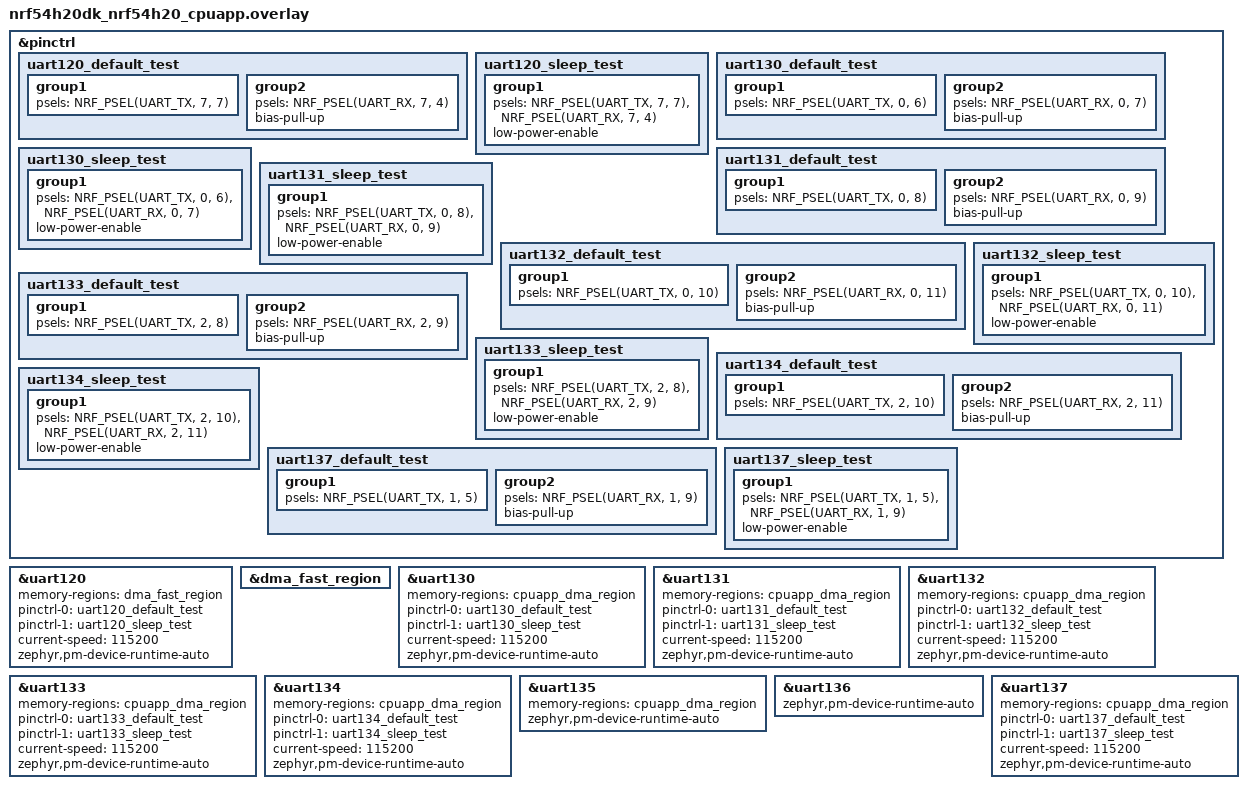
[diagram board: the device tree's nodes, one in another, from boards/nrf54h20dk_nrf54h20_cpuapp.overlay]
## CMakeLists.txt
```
# SPDX-License-Identifier: LicenseRef-Nordic-5-Clause

cmake_minimum_required(VERSION 3.20.0)

find_package(Zephyr REQUIRED HINTS $ENV{ZEPHYR_BASE})
project(uart_instances)

FILE(GLOB app_sources src/*.c)
target_sources(app PRIVATE ${app_sources})
```

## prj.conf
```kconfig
CONFIG_ZTEST=y
CONFIG_TEST_USERSPACE=y
CONFIG_SERIAL=y
CONFIG_UART_USE_RUNTIME_CONFIGURE=y
CONFIG_UART_ASYNC_API=y
```

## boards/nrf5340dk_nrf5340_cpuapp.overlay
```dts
/*
 * Copyright (c) 2026 Nordic Semiconductor ASA
 *
 * SPDX-License-Identifier: LicenseRef-Nordic-5-Clause
 */

&pinctrl {
	uart1_default_test: uart1_default_test {
		group1 {
			psels = <NRF_PSEL(UART_TX, 0, 4)>,
				<NRF_PSEL(UART_RX, 0, 6)>;
			bias-pull-up;
		};
	};

	uart1_sleep_test: uart1_sleep_test {
		group1 {
			psels = <NRF_PSEL(UART_TX, 0, 4)>,
				<NRF_PSEL(UART_RX, 0, 6)>;
			low-power-enable;
		};
	};

	uart2_default_test: uart2_default_test {
		group1 {
			psels = <NRF_PSEL(UART_TX, 1, 4)>,
				<NRF_PSEL(UART_RX, 1, 6)>;
			bias-pull-up;
		};
	};

	uart2_sleep_test: uart2_sleep_test {
		group1 {
			psels = <NRF_PSEL(UART_TX, 1, 4)>,
				<NRF_PSEL(UART_RX, 1, 6)>;
			low-power-enable;
		};
	};

	uart3_default_test: uart3_default_test {
		group1 {
			psels = <NRF_PSEL(UART_TX, 1, 2)>,
				<NRF_PSEL(UART_RX, 1, 3)>;
			bias-pull-up;
		};
	};

	uart3_sleep_test: uart3_sleep_test {
		group1 {
			psels = <NRF_PSEL(UART_TX, 1, 2)>,
				<NRF_PSEL(UART_RX, 1, 3)>;
			low-power-enable;
		};
	};
};

&uart1 {
	status = "okay";
	current-speed = <115200>;
	pinctrl-0 = <&uart1_default_test>;
	pinctrl-1 = <&uart1_sleep_test>;
	pinctrl-names = "default", "sleep";
};

&uart2 {
	status = "okay";
	current-speed = <115200>;
	pinctrl-0 = <&uart2_default_test>;
	pinctrl-1 = <&uart2_sleep_test>;
	pinctrl-names = "default", "sleep";
};

&uart3 {
	status = "okay";
	current-speed = <115200>;
	pinctrl-0 = <&uart3_default_test>;
	pinctrl-1 = <&uart3_sleep_test>;
	pinctrl-names = "default", "sleep";
};
```

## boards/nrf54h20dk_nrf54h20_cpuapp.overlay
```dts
/*
 * Copyright (c) 2025 Nordic Semiconductor ASA
 *
 * SPDX-License-Identifier: LicenseRef-Nordic-5-Clause
 */

&pinctrl {
	uart120_default_test: uart120_default_test {
		group1 {
			psels = <NRF_PSEL(UART_TX, 7, 7)>;
		};

		group2 {
			psels = <NRF_PSEL(UART_RX, 7, 4)>;
			bias-pull-up;
		};
	};

	uart120_sleep_test: uart120_sleep_test {
		group1 {
			psels = <NRF_PSEL(UART_TX, 7, 7)>,
				<NRF_PSEL(UART_RX, 7, 4)>;
			low-power-enable;
		};
	};

	uart130_default_test: uart130_default_test {
		group1 {
			psels = <NRF_PSEL(UART_TX, 0, 6)>;
		};

		group2 {
			psels = <NRF_PSEL(UART_RX, 0, 7)>;
			bias-pull-up;
		};
	};

	uart130_sleep_test: uart130_sleep_test {
		group1 {
			psels = <NRF_PSEL(UART_TX, 0, 6)>,
				<NRF_PSEL(UART_RX, 0, 7)>;
			low-power-enable;
		};
	};

	uart131_default_test: uart131_default_test {
		group1 {
			psels = <NRF_PSEL(UART_TX, 0, 8)>;
		};

		group2 {
			psels = <NRF_PSEL(UART_RX, 0, 9)>;
			bias-pull-up;
		};
	};

	uart131_sleep_test: uart131_sleep_test {
		group1 {
			psels = <NRF_PSEL(UART_TX, 0, 8)>,
				<NRF_PSEL(UART_RX, 0, 9)>;
			low-power-enable;
		};
	};

	uart132_default_test: uart132_default_test {
		group1 {
			psels = <NRF_PSEL(UART_TX, 0, 10)>;
		};

		group2 {
			psels = <NRF_PSEL(UART_RX, 0, 11)>;
			bias-pull-up;
		};
	};

	uart132_sleep_test: uart132_sleep_test {
		group1 {
			psels = <NRF_PSEL(UART_TX, 0, 10)>,
				<NRF_PSEL(UART_RX, 0, 11)>;
			low-power-enable;
		};
	};

	uart133_default_test: uart133_default_test {
		group1 {
			psels = <NRF_PSEL(UART_TX, 2, 8)>;
		};

		group2 {
			psels = <NRF_PSEL(UART_RX, 2, 9)>;
			bias-pull-up;
		};
	};

	uart133_sleep_test: uart133_sleep_test {
		group1 {
			psels = <NRF_PSEL(UART_TX, 2, 8)>,
				<NRF_PSEL(UART_RX, 2, 9)>;
			low-power-enable;
		};
	};

	uart134_default_test: uart134_default_test {
		group1 {
			psels = <NRF_PSEL(UART_TX, 2, 10)>;
		};

		group2 {
			psels = <NRF_PSEL(UART_RX, 2, 11)>;
			bias-pull-up;
		};
	};

	uart134_sleep_test: uart134_sleep_test {
		group1 {
			psels = <NRF_PSEL(UART_TX, 2, 10)>,
				<NRF_PSEL(UART_RX, 2, 11)>;
			low-power-enable;
		};
	};

	/* use default pinctrl for uart135 */

	/* use default pinctrl for uart136 */

	uart137_default_test: uart137_default_test {
		group1 {
			psels = <NRF_PSEL(UART_TX, 1, 5)>;
		};

		group2 {
			psels = <NRF_PSEL(UART_RX, 1, 9)>;
			bias-pull-up;
		};
	};

	uart137_sleep_test: uart137_sleep_test {
		group1 {
			psels = <NRF_PSEL(UART_TX, 1, 5)>,
				<NRF_PSEL(UART_RX, 1, 9)>;
			low-power-enable;
		};
	};
};

&uart120 {
	status = "okay";
	memory-regions = <&dma_fast_region>;
	pinctrl-0 = <&uart120_default_test>;
	pinctrl-1 = <&uart120_sleep_test>;
	pinctrl-names = "default", "sleep";
	current-speed = <115200>;
	zephyr,pm-device-runtime-auto;
};

&dma_fast_region {
	status = "okay";
};

&uart130 {
	status = "okay";
	memory-regions = <&cpuapp_dma_region>;
	pinctrl-0 = <&uart130_default_test>;
	pinctrl-1 = <&uart130_sleep_test>;
	pinctrl-names = "default", "sleep";
	current-speed = <115200>;
	zephyr,pm-device-runtime-auto;
};

&uart131 {
	status = "okay";
	memory-regions = <&cpuapp_dma_region>;
	pinctrl-0 = <&uart131_default_test>;
	pinctrl-1 = <&uart131_sleep_test>;
	pinctrl-names = "default", "sleep";
	current-speed = <115200>;
	zephyr,pm-device-runtime-auto;
};

&uart132 {
	status = "okay";
	memory-regions = <&cpuapp_dma_region>;
	pinctrl-0 = <&uart132_default_test>;
	pinctrl-1 = <&uart132_sleep_test>;
	pinctrl-names = "default", "sleep";
	current-speed = <115200>;
	zephyr,pm-device-runtime-auto;
};

&uart133 {
	status = "okay";
	memory-regions = <&cpuapp_dma_region>;
	pinctrl-0 = <&uart133_default_test>;
	pinctrl-1 = <&uart133_sleep_test>;
	pinctrl-names = "default", "sleep";
	current-speed = <115200>;
	zephyr,pm-device-runtime-auto;
};

&uart134 {
	status = "okay";
	memory-regions = <&cpuapp_dma_region>;
	pinctrl-0 = <&uart134_default_test>;
	pinctrl-1 = <&uart134_sleep_test>;
	pinctrl-names = "default", "sleep";
	current-speed = <115200>;
	zephyr,pm-device-runtime-auto;
};

&uart135 {
	status = "okay";
	memory-regions = <&cpuapp_dma_region>;
	zephyr,pm-device-runtime-auto;
};

&uart136 {
	status = "okay";
	zephyr,pm-device-runtime-auto;
};

&uart137 {
	status = "okay";
	memory-regions = <&cpuapp_dma_region>;
	pinctrl-0 = <&uart137_default_test>;
	pinctrl-1 = <&uart137_sleep_test>;
	pinctrl-names = "default", "sleep";
	current-speed = <115200>;
	zephyr,pm-device-runtime-auto;
};
```

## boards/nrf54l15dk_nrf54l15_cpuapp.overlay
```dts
/*
 * Copyright (c) 2025 Nordic Semiconductor ASA
 *
 * SPDX-License-Identifier: LicenseRef-Nordic-5-Clause
 */

&pinctrl {
	uart00_default_test: uart00_default_test {
		group1 {
			psels = <NRF_PSEL(UART_TX, 2, 8)>,
				<NRF_PSEL(UART_RX, 2, 7)>;
			bias-pull-up;
		};
	};

	uart00_sleep_test: uart00_sleep_test {
		group1 {
			psels = <NRF_PSEL(UART_TX, 2, 8)>,
				<NRF_PSEL(UART_RX, 2, 7)>;
			low-power-enable;
		};
	};

	/* Use default configuration for uart20 */

	uart21_default_test: uart21_default_test {
		group1 {
			psels = <NRF_PSEL(UART_TX, 1, 10)>,
				<NRF_PSEL(UART_RX, 1, 8)>;
			bias-pull-up;
		};
	};

	uart21_sleep_test: uart21_sleep_test {
		group1 {
			psels = <NRF_PSEL(UART_TX, 1, 10)>,
				<NRF_PSEL(UART_RX, 1, 8)>;
			low-power-enable;
		};
	};

	uart22_default_test: uart22_default_test {
		group1 {
			psels = <NRF_PSEL(UART_TX, 1, 9)>,
				<NRF_PSEL(UART_RX, 1, 11)>;
			bias-pull-up;
		};
	};

	uart22_sleep_test: uart22_sleep_test {
		group1 {
			psels = <NRF_PSEL(UART_TX, 1, 9)>,
				<NRF_PSEL(UART_RX, 1, 11)>;
			low-power-enable;
		};
	};

	/* Use default configuration for uart30 */
};

&uart00 {
	status = "okay";
	current-speed = <115200>;
	pinctrl-0 = <&uart00_default_test>;
	pinctrl-1 = <&uart00_sleep_test>;
	pinctrl-names = "default", "sleep";
};

&uart20 {
	status = "okay";
};

&uart21 {
	status = "okay";
	current-speed = <115200>;
	pinctrl-0 = <&uart21_default_test>;
	pinctrl-1 = <&uart21_sleep_test>;
	pinctrl-names = "default", "sleep";
};

&uart22 {
	status = "okay";
	current-speed = <115200>;
	pinctrl-0 = <&uart22_default_test>;
	pinctrl-1 = <&uart22_sleep_test>;
	pinctrl-names = "default", "sleep";
};

&uart30 {
	status = "okay";
};
```

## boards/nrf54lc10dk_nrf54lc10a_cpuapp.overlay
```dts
/*
 * Copyright (c) 2026 Nordic Semiconductor ASA
 *
 * SPDX-License-Identifier: LicenseRef-Nordic-5-Clause
 */

&pinctrl {
	uart20_default_test: uart20_default_test {
		group1 {
			psels = <NRF_PSEL(UART_TX, 1, 2)>,
				<NRF_PSEL(UART_RX, 1, 3)>;
			bias-pull-up;
		};
	};

	uart20_sleep_test: uart20_sleep_test {
		group1 {
			psels = <NRF_PSEL(UART_TX, 1, 2)>,
				<NRF_PSEL(UART_RX, 1, 3)>;
			low-power-enable;
		};
	};

	uart21_default_test: uart21_default_test {
		group1 {
			psels = <NRF_PSEL(UART_TX, 1, 4)>,
				<NRF_PSEL(UART_RX, 1, 5)>;
			bias-pull-up;
		};
	};

	uart21_sleep_test: uart21_sleep_test {
		group1 {
			psels = <NRF_PSEL(UART_TX, 1, 4)>,
				<NRF_PSEL(UART_RX, 1, 5)>;
			low-power-enable;
		};
	};
};

&uart20 {
	status = "okay";
	current-speed = <115200>;
	pinctrl-0 = <&uart20_default_test>;
	pinctrl-1 = <&uart20_sleep_test>;
	pinctrl-names = "default", "sleep";
};

&uart21 {
	status = "okay";
	current-speed = <115200>;
	pinctrl-0 = <&uart21_default_test>;
	pinctrl-1 = <&uart21_sleep_test>;
	pinctrl-names = "default", "sleep";
};

&uart30 {
	status = "okay";
};

&gpio1 {
	status = "okay";
};
```

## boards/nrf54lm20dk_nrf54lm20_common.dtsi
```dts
/*
 * Copyright (c) 2026 Nordic Semiconductor ASA
 *
 * SPDX-License-Identifier: LicenseRef-Nordic-5-Clause
 */

&pinctrl {
	uart00_default_test: uart00_default_test {
		group1 {
			psels = <NRF_PSEL(UART_TX, 2, 2)>,
				<NRF_PSEL(UART_RX, 2, 1)>;
			bias-pull-up;
		};
	};

	uart00_sleep_test: uart00_sleep_test {
		group1 {
			psels = <NRF_PSEL(UART_TX, 2, 2)>,
				<NRF_PSEL(UART_RX, 2, 1)>;
			low-power-enable;
		};
	};

	/* Use default configuration for uart20 */

	uart21_default_test: uart21_default_test {
		group1 {
			psels = <NRF_PSEL(UART_TX, 3, 0)>,
				<NRF_PSEL(UART_RX, 3, 1)>;
			bias-pull-up;
		};
	};

	uart21_sleep_test: uart21_sleep_test {
		group1 {
			psels = <NRF_PSEL(UART_TX, 3, 0)>,
				<NRF_PSEL(UART_RX, 3, 1)>;
			low-power-enable;
		};
	};

	uart22_default_test: uart22_default_test {
		group1 {
			psels = <NRF_PSEL(UART_TX, 3, 2)>,
				<NRF_PSEL(UART_RX, 3, 3)>;
			bias-pull-up;
		};
	};

	uart22_sleep_test: uart22_sleep_test {
		group1 {
			psels = <NRF_PSEL(UART_TX, 3, 2)>,
				<NRF_PSEL(UART_RX, 3, 3)>;
			low-power-enable;
		};
	};

	uart23_default_test: uart23_default_test {
		group1 {
			psels = <NRF_PSEL(UART_TX, 3, 4)>,
				<NRF_PSEL(UART_RX, 3, 5)>;
			bias-pull-up;
		};
	};

	uart23_sleep_test: uart23_sleep_test {
		group1 {
			psels = <NRF_PSEL(UART_TX, 3, 4)>,
				<NRF_PSEL(UART_RX, 3, 5)>;
			low-power-enable;
		};
	};

	uart24_default_test: uart24_default_test {
		group1 {
			psels = <NRF_PSEL(UART_TX, 3, 6)>,
				<NRF_PSEL(UART_RX, 3, 7)>;
			bias-pull-up;
		};
	};

	uart24_sleep_test: uart24_sleep_test {
		group1 {
			psels = <NRF_PSEL(UART_TX, 3, 6)>,
				<NRF_PSEL(UART_RX, 3, 7)>;
			low-power-enable;
		};
	};

	/* Use default configuration for uart30 */
};

&uart00 {
	status = "okay";
	current-speed = <115200>;
	pinctrl-0 = <&uart00_default_test>;
	pinctrl-1 = <&uart00_sleep_test>;
	pinctrl-names = "default", "sleep";
};

&uart20 {
	status = "okay";
};

&uart21 {
	status = "okay";
	current-speed = <115200>;
	pinctrl-0 = <&uart21_default_test>;
	pinctrl-1 = <&uart21_sleep_test>;
	pinctrl-names = "default", "sleep";
};

&uart22 {
	status = "okay";
	current-speed = <115200>;
	pinctrl-0 = <&uart22_default_test>;
	pinctrl-1 = <&uart22_sleep_test>;
	pinctrl-names = "default", "sleep";
};

&uart23 {
	status = "okay";
	current-speed = <115200>;
	pinctrl-0 = <&uart23_default_test>;
	pinctrl-1 = <&uart23_sleep_test>;
	pinctrl-names = "default", "sleep";
};

&uart24 {
	status = "okay";
	current-speed = <115200>;
	pinctrl-0 = <&uart24_default_test>;
	pinctrl-1 = <&uart24_sleep_test>;
	pinctrl-names = "default", "sleep";
};

&uart30 {
	status = "okay";
};
```

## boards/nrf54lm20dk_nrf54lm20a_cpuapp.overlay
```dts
/*
 * Copyright (c) 2025 Nordic Semiconductor ASA
 *
 * SPDX-License-Identifier: LicenseRef-Nordic-5-Clause
 */

&pinctrl {
	uart00_default_test: uart00_default_test {
		group1 {
			psels = <NRF_PSEL(UART_TX, 2, 2)>,
				<NRF_PSEL(UART_RX, 2, 1)>;
			bias-pull-up;
		};
	};

	uart00_sleep_test: uart00_sleep_test {
		group1 {
			psels = <NRF_PSEL(UART_TX, 2, 2)>,
				<NRF_PSEL(UART_RX, 2, 1)>;
			low-power-enable;
		};
	};

	/* Use default configuration for uart20 */

	uart21_default_test: uart21_default_test {
		group1 {
			psels = <NRF_PSEL(UART_TX, 3, 0)>,
				<NRF_PSEL(UART_RX, 3, 1)>;
			bias-pull-up;
		};
	};

	uart21_sleep_test: uart21_sleep_test {
		group1 {
			psels = <NRF_PSEL(UART_TX, 3, 0)>,
				<NRF_PSEL(UART_RX, 3, 1)>;
			low-power-enable;
		};
	};

	uart22_default_test: uart22_default_test {
		group1 {
			psels = <NRF_PSEL(UART_TX, 3, 2)>,
				<NRF_PSEL(UART_RX, 3, 3)>;
			bias-pull-up;
		};
	};

	uart22_sleep_test: uart22_sleep_test {
		group1 {
			psels = <NRF_PSEL(UART_TX, 3, 2)>,
				<NRF_PSEL(UART_RX, 3, 3)>;
			low-power-enable;
		};
	};

	uart23_default_test: uart23_default_test {
		group1 {
			psels = <NRF_PSEL(UART_TX, 3, 4)>,
				<NRF_PSEL(UART_RX, 3, 5)>;
			bias-pull-up;
		};
	};

	uart23_sleep_test: uart23_sleep_test {
		group1 {
			psels = <NRF_PSEL(UART_TX, 3, 4)>,
				<NRF_PSEL(UART_RX, 3, 5)>;
			low-power-enable;
		};
	};

	uart24_default_test: uart24_default_test {
		group1 {
			psels = <NRF_PSEL(UART_TX, 3, 6)>,
				<NRF_PSEL(UART_RX, 3, 7)>;
			bias-pull-up;
		};
	};

	uart24_sleep_test: uart24_sleep_test {
		group1 {
			psels = <NRF_PSEL(UART_TX, 3, 6)>,
				<NRF_PSEL(UART_RX, 3, 7)>;
			low-power-enable;
		};
	};

	/* Use default configuration for uart30 */
};

&uart00 {
	status = "okay";
	current-speed = <115200>;
	pinctrl-0 = <&uart00_default_test>;
	pinctrl-1 = <&uart00_sleep_test>;
	pinctrl-names = "default", "sleep";
};

&uart20 {
	status = "okay";
};

&uart21 {
	status = "okay";
	current-speed = <115200>;
	pinctrl-0 = <&uart21_default_test>;
	pinctrl-1 = <&uart21_sleep_test>;
	pinctrl-names = "default", "sleep";
};

&uart22 {
	status = "okay";
	current-speed = <115200>;
	pinctrl-0 = <&uart22_default_test>;
	pinctrl-1 = <&uart22_sleep_test>;
	pinctrl-names = "default", "sleep";
};

&uart23 {
	status = "okay";
	current-speed = <115200>;
	pinctrl-0 = <&uart23_default_test>;
	pinctrl-1 = <&uart23_sleep_test>;
	pinctrl-names = "default", "sleep";
};

&uart24 {
	status = "okay";
	current-speed = <115200>;
	pinctrl-0 = <&uart24_default_test>;
	pinctrl-1 = <&uart24_sleep_test>;
	pinctrl-names = "default", "sleep";
};

&uart30 {
	status = "okay";
};
```

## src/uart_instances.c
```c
/*
 * Copyright (c) 2025, Nordic Semiconductor ASA
 *
 * SPDX-License-Identifier: LicenseRef-Nordic-5-Clause
 */

#include <zephyr/kernel.h>
#include <zephyr/drivers/uart.h>
#include <zephyr/ztest.h>

#include <zephyr/logging/log.h>
LOG_MODULE_REGISTER(test);

#define DEVICE_DT_GET_AND_COMMA(node_id) DEVICE_DT_GET(node_id),
/* Generate a list of devices for all instances of the "compat" */
#define DEVS_FOR_DT_COMPAT(compat) \
	DT_FOREACH_STATUS_OKAY(compat, DEVICE_DT_GET_AND_COMMA)

static const struct device *const devices[] = {
#ifdef CONFIG_UART_NRFX
	DEVS_FOR_DT_COMPAT(nordic_nrf_uarte)
#endif
};

typedef void (*test_func_t)(const struct device *dev);
typedef bool (*capability_func_t)(const struct device *dev);

static void setup_instance(const struct device *dev)
{
	/* Left for future test expansion. */
}

static void tear_down_instance(const struct device *dev)
{
	/* Left for future test expansion. */
}

static void test_all_instances(test_func_t func, capability_func_t capability_check)
{
	int devices_skipped = 0;

	zassert_true(ARRAY_SIZE(devices) > 0, "No device found");
	for (int i = 0; i < ARRAY_SIZE(devices); i++) {
		setup_instance(devices[i]);
		TC_PRINT("\nInstance %u: ", i + 1);
		if ((capability_check == NULL) ||
		     capability_check(devices[i])) {
			TC_PRINT("Testing %s\n", devices[i]->name);
			func(devices[i]);
		} else {
			TC_PRINT("Skipped for %s\n", devices[i]->name);
			devices_skipped++;
		}
		tear_down_instance(devices[i]);
		/* Allow logs to be printed. */
		k_sleep(K_MSEC(100));
	}
	if (devices_skipped == ARRAY_SIZE(devices)) {
		ztest_test_skip();
	}
}


/**
 * Test validates if instance can send data.
 */
static void test_send_any_data_instance(const struct device *dev)
{
	struct uart_config test_uart_config;
	const uint8_t tx_buf[1] = {0x23};
	int ret = 0;

	ret = uart_config_get(dev, &test_uart_config);
	zassert_equal(ret, 0, "uart_config_get() failed %d", ret);

	test_uart_config.parity = UART_CFG_PARITY_NONE;
	test_uart_config.stop_bits = UART_CFG_STOP_BITS_1;
	test_uart_config.flow_ctrl = UART_CFG_FLOW_CTRL_NONE;
	test_uart_config.baudrate = 115200;

	ret = uart_configure(dev, &test_uart_config);
	zassert_equal(0, ret, "%s: uart_configure() failed %d", dev->name, ret);

	ret = uart_tx(dev, tx_buf, sizeof(tx_buf), 0);
	zassert_equal(0, ret, "%s: uart_tx() failed %d", dev->name, ret);

	/* Data reception is not tested. */
}

static bool test_send_any_data_capable(const struct device *dev)
{
	return true;
}

ZTEST(uart_instances, test_send_any_data)
{
	test_all_instances(test_send_any_data_instance, test_send_any_data_capable);
}

static void *suite_setup(void)
{
	int i;

	TC_PRINT("uart_instances test executed on %s\n", CONFIG_BOARD_TARGET);
	TC_PRINT("===================================================================\n");

	for (i = 0; i < ARRAY_SIZE(devices); i++) {
		zassert_true(device_is_ready(devices[i]),
			     "Device %s is not ready", devices[i]->name);
		k_object_access_grant(devices[i], k_current_get());
	}

	return NULL;
}

ZTEST_SUITE(uart_instances, NULL, suite_setup, NULL, NULL, NULL);
```
